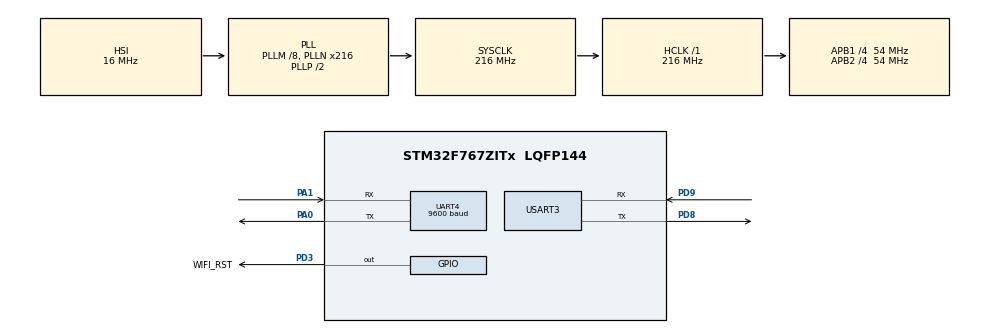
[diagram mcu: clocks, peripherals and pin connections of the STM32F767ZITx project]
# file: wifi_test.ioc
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FREERTOS.Tasks01=defaultTask,0,128,StartDefaultTask,Default,NULL,Dynamic,NULL,NULL;wifiTask,0,1024,vWifi_taskFunction,As external,NULL,Dynamic,NULL,NULL
Mcu.Family=STM32F7
Mcu.Name=STM32F767ZITx
Mcu.Package=LQFP144
NVIC.PriorityGroup=NVIC_PRIORITYGROUP_4
NVIC.TIM1_UP_TIM10_IRQn=true\:0\:0\:false\:false\:true\:false\:false\:true
NVIC.TimeBase=TIM1_UP_TIM10_IRQn
NVIC.TimeBaseIP=TIM1
NVIC.UART4_IRQn=true\:5\:0\:false\:false\:true\:true\:true\:true
NVIC.USART3_IRQn=true\:5\:0\:false\:false\:true\:true\:true\:true
PA0/WKUP.GPIO_PuPd=GPIO_NOPULL
PA0/WKUP.Mode=Asynchronous
PA0/WKUP.Signal=UART4_TX
PA1.GPIO_ModeDefaultPP=GPIO_MODE_AF_PP
PA1.GPIO_PuPd=GPIO_NOPULL
PA1.Mode=Asynchronous
PA1.Signal=UART4_RX
PA13.Mode=Serial_Wire
PA13.Signal=SYS_JTMS-SWDIO
PA14.Mode=Serial_Wire
PA14.Signal=SYS_JTCK-SWCLK
PD3.GPIO_Label=WIFI_RST
PD3.GPIO_PuPd=GPIO_PULLUP
PD3.Signal=GPIO_Output
PD8.Mode=Asynchronous
PD8.Signal=USART3_TX
PD9.Mode=Asynchronous
PD9.Signal=USART3_RX
ProjectManager.HeapSize=0x200
ProjectManager.StackSize=0x400
ProjectManager.TargetToolchain=MDK-ARM V5
RCC.48MHZClocksFreq_Value=24000000
RCC.AHBFreq_Value=216000000
RCC.APB1CLKDivider=RCC_HCLK_DIV4
RCC.APB1Freq_Value=54000000
RCC.APB1TimFreq_Value=108000000
RCC.APB2CLKDivider=RCC_HCLK_DIV4
RCC.APB2Freq_Value=54000000
RCC.APB2TimFreq_Value=108000000
RCC.CortexFreq_Value=216000000
RCC.HCLKFreq_Value=216000000
RCC.HSE_VALUE=16000000
RCC.HSI_VALUE=16000000
RCC.LSE_VALUE=32768
RCC.PLLM=8
RCC.PLLMUL=RCC_PLL_MUL9
RCC.PLLN=216
RCC.PRESCALERUSB=RCC_USBCLKSOURCE_PLL_DIV1_5
RCC.SYSCLKFreq_VALUE=216000000
RCC.SYSCLKSource=RCC_SYSCLKSOURCE_PLLCLK
RCC.SYSCLKSourceVirtual=RCC_SYSCLKSOURCE_PLLCLK
RCC.USBFreq_Value=216000000
RCC.VCOOutputFreq_Value=432000000
UART4.BaudRate=9600
UART4.SwapParam=UART_ADVFEATURE_SWAP_DISABLE
USART3.VirtualMode-Asynchronous=VM_ASYNC
VP_FREERTOS_VS_CMSIS_V1.Mode=CMSIS_V1
VP_SYS_VS_tim1.Mode=TIM1
board=NUCLEO-F767ZI

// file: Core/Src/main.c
/* USER CODE BEGIN Header */
/**
  ******************************************************************************
  * @file           : main.c
  * @brief          : Main program body
  ******************************************************************************
  * @attention
  *
  * <h2><center>&copy; Copyright (c) 2019 STMicroelectronics.
  * All rights reserved.</center></h2>
  *
  * This software component is licensed by ST under BSD 3-Clause license,
  * the "License"; You may not use this file except in compliance with the
  * License. You may obtain a copy of the License at:
  *                        opensource.org/licenses/BSD-3-Clause
  *
  ******************************************************************************
  */
/* USER CODE END Header */

#include "main.h"
#include "cmsis_os.h"
#include "usart.h"
#include "gpio.h"

/* USER CODE BEGIN Includes */
#include "wifi.h"
/* USER CODE END Includes */

void SystemClock_Config(void);
void MX_FREERTOS_Init(void);

int main(void)
{

  /* MCU Configuration--------------------------------------------------------*/

  /* Reset of all peripherals, Initializes the Flash interface and the Systick. */
  HAL_Init();

  /* Configure the system clock */
  SystemClock_Config();

  /* Initialize all configured peripherals */
  MX_GPIO_Init();
  MX_UART4_Init();
  MX_USART3_UART_Init();
  /* USER CODE BEGIN 2 */

	printf("esp8266 test\r\n");

	wifi_init();

  /* USER CODE END 2 */

  /* Call init function for freertos objects (in freertos.c) */
  MX_FREERTOS_Init();

  /* Start scheduler */
  osKernelStart();

  /* We should never get here as control is now taken by the scheduler */

  /* Infinite loop */
  while (1)
  {

  }
}

void SystemClock_Config(void)
{
  RCC_OscInitTypeDef RCC_OscInitStruct = {0};
  RCC_ClkInitTypeDef RCC_ClkInitStruct = {0};
  RCC_PeriphCLKInitTypeDef PeriphClkInitStruct = {0};

  /** Configure the main internal regulator output voltage
  */
  __HAL_RCC_PWR_CLK_ENABLE();
  __HAL_PWR_VOLTAGESCALING_CONFIG(PWR_REGULATOR_VOLTAGE_SCALE1);
  /** Initializes the CPU, AHB and APB busses clocks
  */
  RCC_OscInitStruct.OscillatorType = RCC_OSCILLATORTYPE_HSI;
  RCC_OscInitStruct.HSIState = RCC_HSI_ON;
  RCC_OscInitStruct.HSICalibrationValue = RCC_HSICALIBRATION_DEFAULT;
  RCC_OscInitStruct.PLL.PLLState = RCC_PLL_ON;
  RCC_OscInitStruct.PLL.PLLSource = RCC_PLLSOURCE_HSI;
  RCC_OscInitStruct.PLL.PLLM = 8;
  RCC_OscInitStruct.PLL.PLLN = 216;
  RCC_OscInitStruct.PLL.PLLP = RCC_PLLP_DIV2;
  RCC_OscInitStruct.PLL.PLLQ = 2;
  if (HAL_RCC_OscConfig(&RCC_OscInitStruct) != HAL_OK)
  {
    Error_Handler();
  }
  /** Activate the Over-Drive mode
  */
  if (HAL_PWREx_EnableOverDrive() != HAL_OK)
  {
    Error_Handler();
  }
  /** Initializes the CPU, AHB and APB busses clocks
  */
  RCC_ClkInitStruct.ClockType = RCC_CLOCKTYPE_HCLK|RCC_CLOCKTYPE_SYSCLK
                              |RCC_CLOCKTYPE_PCLK1|RCC_CLOCKTYPE_PCLK2;
  RCC_ClkInitStruct.SYSCLKSource = RCC_SYSCLKSOURCE_PLLCLK;
  RCC_ClkInitStruct.AHBCLKDivider = RCC_SYSCLK_DIV1;
  RCC_ClkInitStruct.APB1CLKDivider = RCC_HCLK_DIV4;
  RCC_ClkInitStruct.APB2CLKDivider = RCC_HCLK_DIV4;

  if (HAL_RCC_ClockConfig(&RCC_ClkInitStruct, FLASH_LATENCY_7) != HAL_OK)
  {
    Error_Handler();
  }
  PeriphClkInitStruct.PeriphClockSelection = RCC_PERIPHCLK_USART3|RCC_PERIPHCLK_UART4;
  PeriphClkInitStruct.Usart3ClockSelection = RCC_USART3CLKSOURCE_PCLK1;
  PeriphClkInitStruct.Uart4ClockSelection = RCC_UART4CLKSOURCE_PCLK1;
  if (HAL_RCCEx_PeriphCLKConfig(&PeriphClkInitStruct) != HAL_OK)
  {
    Error_Handler();
  }
}

void HAL_TIM_PeriodElapsedCallback(TIM_HandleTypeDef *htim)
{
  if (htim->Instance == TIM1) {
    HAL_IncTick();
  }
}

void Error_Handler(void)
{
}

/************************ (C) COPYRIGHT STMicroelectronics *****END OF FILE****/

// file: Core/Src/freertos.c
/* USER CODE BEGIN Header */
/**
  ******************************************************************************
  * File Name          : freertos.c
  * Description        : Code for freertos applications
  ******************************************************************************
  * @attention
  *
  * <h2><center>&copy; Copyright (c) 2020 STMicroelectronics.
  * All rights reserved.</center></h2>
  *
  * This software component is licensed by ST under Ultimate Liberty license
  * SLA0044, the "License"; You may not use this file except in compliance with
  * the License. You may obtain a copy of the License at:
  *                             www.st.com/SLA0044
  *
  ******************************************************************************
  */
/* USER CODE END Header */

#include "FreeRTOS.h"
#include "task.h"
#include "main.h"
#include "cmsis_os.h"

osThreadId defaultTaskHandle;
osThreadId wifiTaskHandle;

void StartDefaultTask(void const * argument);
extern void vWifi_taskFunction(void const * argument);

void MX_FREERTOS_Init(void); /* (MISRA C 2004 rule 8.1) */

void MX_FREERTOS_Init(void) {

  /* Create the thread(s) */
  /* definition and creation of defaultTask */
  osThreadDef(defaultTask, StartDefaultTask, osPriorityNormal, 0, 128);
  defaultTaskHandle = osThreadCreate(osThread(defaultTask), NULL);

  /* definition and creation of wifiTask */
  osThreadDef(wifiTask, vWifi_taskFunction, osPriorityNormal, 0, 1024);
  wifiTaskHandle = osThreadCreate(osThread(wifiTask), NULL);

}

void StartDefaultTask(void const * argument)
{

  for(;;)
  {
    osDelay(1);
  }
}

/************************ (C) COPYRIGHT STMicroelectronics *****END OF FILE****/
